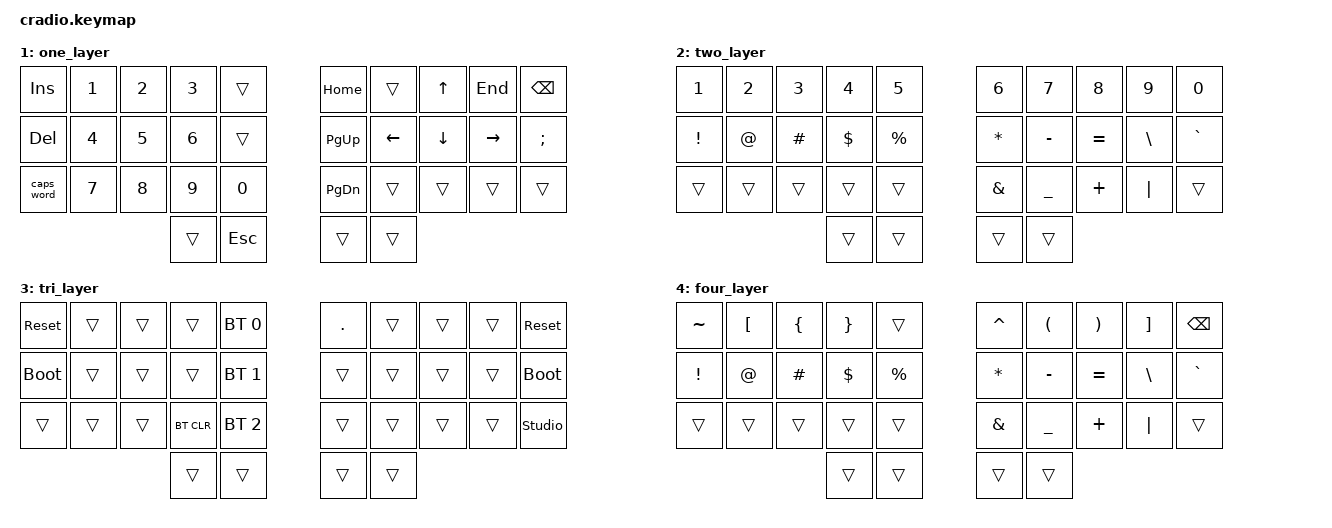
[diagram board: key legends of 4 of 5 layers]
// Copyright (c) 2022 The ZMK Contributors
// SPDX-License-Identifier: MIT

#include <behaviors.dtsi>
#include <dt-bindings/zmk/keys.h>
#include <dt-bindings/zmk/bt.h>

// Define layers
#define L_DL 0 // Default layer
#define L_LL 1 // Left layer
#define L_RL 2 // Right layer
#define L_ML 3 // Setup layer
#define L_P 3 // Plus layer

// Home row mods macro
// For some reson LEFT_CONTROL its Start
#define HRML(k1,k2,k3,k4) &ht LSHFT k1  &ht LEFT_ALT k2  &ht LEFT_CONTROL k3  &ht LGUI k4
#define HRMR(k1,k2,k3,k4) &ht RGUI k1  &ht RCTRL k2  &ht RALT k3  &ht RSHFT k4

/ {
    behaviors {
        ht: hold_tap {
            compatible = "zmk,behavior-hold-tap";
            #binding-cells = <2>;
            flavor = "tap-preferred";
            tapping-term-ms = <220>;
            quick-tap-ms = <150>;
            require-prior-idle-ms = <100>;
            bindings = <&kp>, <&kp>;
        };
    };

    // When (if-layers) are active ( both at same time ), then (then-layer) will be activated
    conditional_layers {
        compatible = "zmk,conditional-layers";
        tri_layer {
            if-layers = <1 2>;
            then-layer = <3>;
        };
    };
    
    combos {
        compatible = "zmk,combos";

        // Here pressing first key and then the second key within 50ms will trigger the combo
        // The combo will send ESC key when Q and W are pressed within 50ms
        combo_esc {
            timeout-ms = <50>;
            key-positions = <0 1>;
            bindings = <&kp ESC>;
        };

        combo_backspace {
            timeout-ms = <50>;
            key-positions = <8 9>;
            bindings = <&kp BSPC>;
        };
    };

    keymap {
        compatible = "zmk,keymap";
        default_layer {
            bindings = <
        //╭──────────┬──────────┬──────────┬──────────┬──────────╮   ╭──────────┬──────────┬──────────┬──────────┬──────────╮
        //│  Q       │  W       │  F       │  P       │  G       │   │  J       │  L       │  U       │  Y       │  ; :     │
            &kp Q      &kp W      &kp F      &kp P      &kp G          &kp J      &kp L      &kp U      &kp Y      &kp SCLN
        //├──────────┼──────────┼──────────┼──────────┼──────────┤   ├──────────┼──────────┼──────────┼──────────┼──────────┤
        //│  A       │  R       │  S       │  T       │  D       │   │  H       │  N       │  E       │  I       │  O       │
            HRML(A,        R,         S,         T)     &kp D          &kp H      HRMR(N,        E,         I,        O)
        //├──────────┼──────────┼──────────┼──────────┼──────────┤   ├──────────┼──────────┼──────────┼──────────┼──────────┤
        //│  Z       │  X       │  C       │  V       │  B       │   │  K       │  M       │ , <      │ . >      │ / ?      │
            &kp Z      &kp X      &kp C      &kp V      &kp B          &kp K      &kp M      &kp COMMA  &kp DOT    &kp FSLH
        //╰──────────┴──────────┴──────────┼──────────┼──────────┤   ├──────────┼──────────┼──────────┴──────────┴──────────╯
                                            &lt 2 TAB  &lt 4 ENTER     &lt 1 BSPC  &kp SPACE 
        //                                 ╰──────────┴──────────╯   ╰──────────┴──────────╯
            >;
        };

        one_layer {
            bindings = <
        //╭──────────┬──────────┬──────────┬──────────┬──────────╮   ╭──────────┬──────────┬──────────┬──────────┬──────────╮
        //│ INSERT   │  1       │  2       │  3       │          │   │ HOME     │          │      UP  │ END      │ Backspace│
            &kp INS    &kp N1     &kp N2     &kp N3     &trans         &kp HOME   &trans     &kp UP     &kp END    &kp BSPC
        //├──────────┼──────────┼──────────┼──────────┼──────────┤   ├──────────┼──────────┼──────────┼──────────┼──────────┤
        //│ DELETE   │  4       │  5       │  6       │          │   │ PAGE UP  │ LEFT     │ DOWN     │ RIGHT    │  ;       │
            &kp DEL    &kp N4     &kp N5     &kp N6     &trans         &kp PG_UP  &kp LEFT   &kp DOWN   &kp RIGHT   &kp SEMI
        //├──────────┼──────────┼──────────┼──────────┼──────────┤   ├──────────┼──────────┼──────────┼──────────┼──────────┤
        //│ CAPS     │  7       │  8       │  9       │  0       │   │ PAGE DN  │          │          │          │          │
           &caps_word  &kp N7     &kp N8     &kp N9     &kp N0         &kp PG_DN    &trans     &trans     &trans     &trans
        //╰──────────┴──────────┴──────────┼──────────┼──────────┤   ├──────────┼──────────┼──────────┴──────────┴──────────╯
                                            &trans     &kp ESC        &trans     &trans
        //                                 ╰──────────┴──────────╯   ╰──────────┴──────────╯
            >;
        };

        two_layer {
            bindings = <
        //╭──────────┬──────────┬──────────┬──────────┬──────────╮   ╭──────────┬──────────┬──────────┬──────────┬──────────╮
        //│ 1  !     │  2 @     │  3 #     │  4 $     │ 5 %      │   │  6  ^    │  7 &     │  8 *     │  9 (     │0  )      │
            &kp N1      &kp N2     &kp N3    &kp N4     &kp N5         &kp N6     &kp N7   &kp N8       &kp N9    &kp N0
        //├──────────┼──────────┼──────────┼──────────┼──────────┤   ├──────────┼──────────┼──────────┼──────────┼──────────┤
        //│  !       │  @       │  #       │  $       │  %       │   │  *       │  -       │  =       │  \       │  `       │
            &kp EXCL   &kp AT     &kp HASH   &kp DLLR   &kp PRCNT      &kp ASTRK  &kp MINUS  &kp EQUAL  &kp BSLH   &kp GRAVE
        //├──────────┼──────────┼──────────┼──────────┼──────────┤   ├──────────┼──────────┼──────────┼──────────┼──────────┤
        //│          │          │          │          │          │   │  &       │  _       │  +       │  │       │          │
            &trans     &trans     &trans     &trans     &trans         &kp AMPS   &kp UNDER  &kp PLUS   &kp PIPE   &trans
        //╰──────────┴──────────┴──────────┼──────────┼──────────┤   ├──────────┼──────────┼──────────┴──────────┴──────────╯
                                             &trans     &trans         &trans     &trans
        //                                 ╰──────────┴──────────╯   ╰──────────┴──────────╯
            >;
        };

        tri_layer {
            bindings = <
        //╭──────────┬──────────┬──────────┬──────────┬──────────╮   ╭──────────┬──────────┬──────────┬──────────┬──────────╮
        //│ RESET    │          │          │          │PROFILE 0 │   │  .       │          │          │          │  RESET   │
           &sys_reset  &trans     &trans     &trans    &bt BT_SEL 0    &kp DOT     &trans     &trans     &trans    &sys_reset
        //├──────────┼──────────┼──────────┼──────────┼──────────┤   ├──────────┼──────────┼──────────┼──────────┼──────────┤
        //│BOOTLOADER│          │          │          │PROFILE 1 │   │          │          │          │          │BOOTLOADER│
          &bootloader  &trans     &trans     &trans    &bt BT_SEL 1    &trans     &trans     &trans     &trans    &bootloader
        //├──────────┼──────────┼──────────┼──────────┼──────────┤   ├──────────┼──────────┼──────────┼──────────┼──────────┤
        //│          │          │          │ CLEAR BT │PROFILE 2 │   │          │          │          │          │ Studio   │
            &trans     &trans     &trans    &bt BT_CLR &bt BT_SEL 2    &trans     &trans     &trans     &trans     &studio_unlock
        //╰──────────┴──────────┴──────────┼──────────┼──────────┤   ├──────────┼──────────┼──────────┴──────────┴──────────╯
                                             &trans     &trans         &trans     &trans
        //                                 ╰──────────┴──────────╯   ╰──────────┴──────────╯
            >;
        };

        four_layer {
            bindings = <
        //╭──────────┬──────────┬──────────┬──────────┬──────────╮   ╭──────────┬──────────┬──────────┬──────────┬──────────╮
        //│ ~        │  [       │  {       │  }       │          │   │  ^       │  (       │  )       │  ]       │Backspace │
            &kp TILDE  &kp LBKT   &kp LBRC   &kp RBRC   &trans         &kp CARET  &kp LPAR   &kp RPAR   &kp RBKT   &kp BSPC
        //├──────────┼──────────┼──────────┼──────────┼──────────┤   ├──────────┼──────────┼──────────┼──────────┼──────────┤
        //│  !       │  @       │  #       │  $       │  %       │   │  *       │  -       │  =       │  \       │  `       │
            &kp EXCL   &kp AT     &kp HASH   &kp DLLR   &kp PRCNT      &kp ASTRK  &kp MINUS  &kp EQUAL  &kp BSLH   &kp GRAVE
        //├──────────┼──────────┼──────────┼──────────┼──────────┤   ├──────────┼──────────┼──────────┼──────────┼──────────┤
        //│          │          │          │          │          │   │  &       │  _       │  +       │  │       │          │
            &trans     &trans     &trans     &trans     &trans         &kp AMPS   &kp UNDER  &kp PLUS   &kp PIPE   &trans
        //╰──────────┴──────────┴──────────┼──────────┼──────────┤   ├──────────┼──────────┼──────────┴──────────┴──────────╯
                                             &trans     &trans         &trans     &trans
        //                                 ╰──────────┴──────────╯   ╰──────────┴──────────╯
            >;
        };
    };
};
